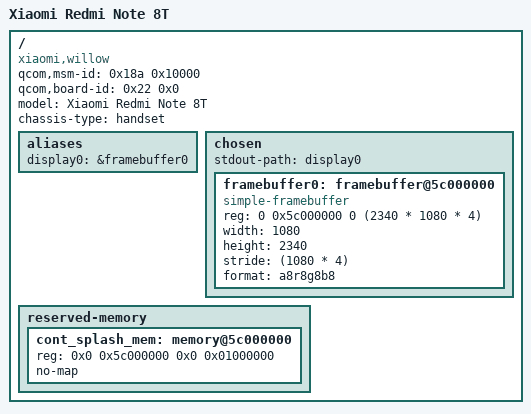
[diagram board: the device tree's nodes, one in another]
// SPDX-License-Identifier: BSD-3-Clause
/*
 * Copyright (c) 2022
 */

/dts-v1/;

#include "sm6125.dtsi"
#include <dt-bindings/gpio/gpio.h>
#include <dt-bindings/input/input.h>
#include <dt-bindings/input/gpio-keys.h>

/delete-node/ &cont_splash_mem;
/delete-node/ &sdhc_2;//FIXME: check downstream code

/ {
	/* required for bootloader to select correct board */
	qcom,msm-id = <0x18a 0x10000>;
	qcom,board-id = <0x22 0x0>;

	model = "Xiaomi Redmi Note 8T";
	compatible = "xiaomi,willow", "qcom,sm6125";
	chassis-type = "handset";

	aliases {
		display0 = &framebuffer0;
 	};

	chosen {
		#address-cells = <2>;
		#size-cells = <2>;
		ranges;

		/* HACK: Use "display0" for simplefb */
		stdout-path = "display0";

		framebuffer0: framebuffer@5c000000 {
			compatible = "simple-framebuffer";
			reg = <0 0x5c000000 0 (2340 * 1080 * 4)>;
			width = <1080>;
			height = <2340>;
			stride = <(1080 * 4)>;
			format = "a8r8g8b8";
		};
	};

	reserved-memory {
		#address-cells = <2>;
		#size-cells = <2>;
		
		cont_splash_mem: memory@5c000000 {
			reg = <0x0 0x5c000000 0x0 0x01000000>;
			no-map;
		};
	};
};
